AUTOSAR XML (schema 4.0)
package /ADAS_Components
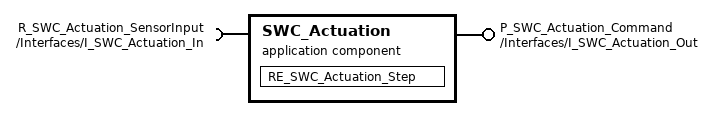
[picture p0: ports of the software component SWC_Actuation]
  application sw component type SWC_Actuation  # AUTOSAR Application SWC SWC_Actuation for ADAS control
    provide port P_SWC_Actuation_Command: provided-interface=/Interfaces/I_SWC_Actuation_Out
    require port R_SWC_Actuation_SensorInput: required-interface=/Interfaces/I_SWC_Actuation_In
    behavior SWC_Actuation_Behavior
      runnable RE_SWC_Actuation_Step: symbol=SWC_Actuation_Step
